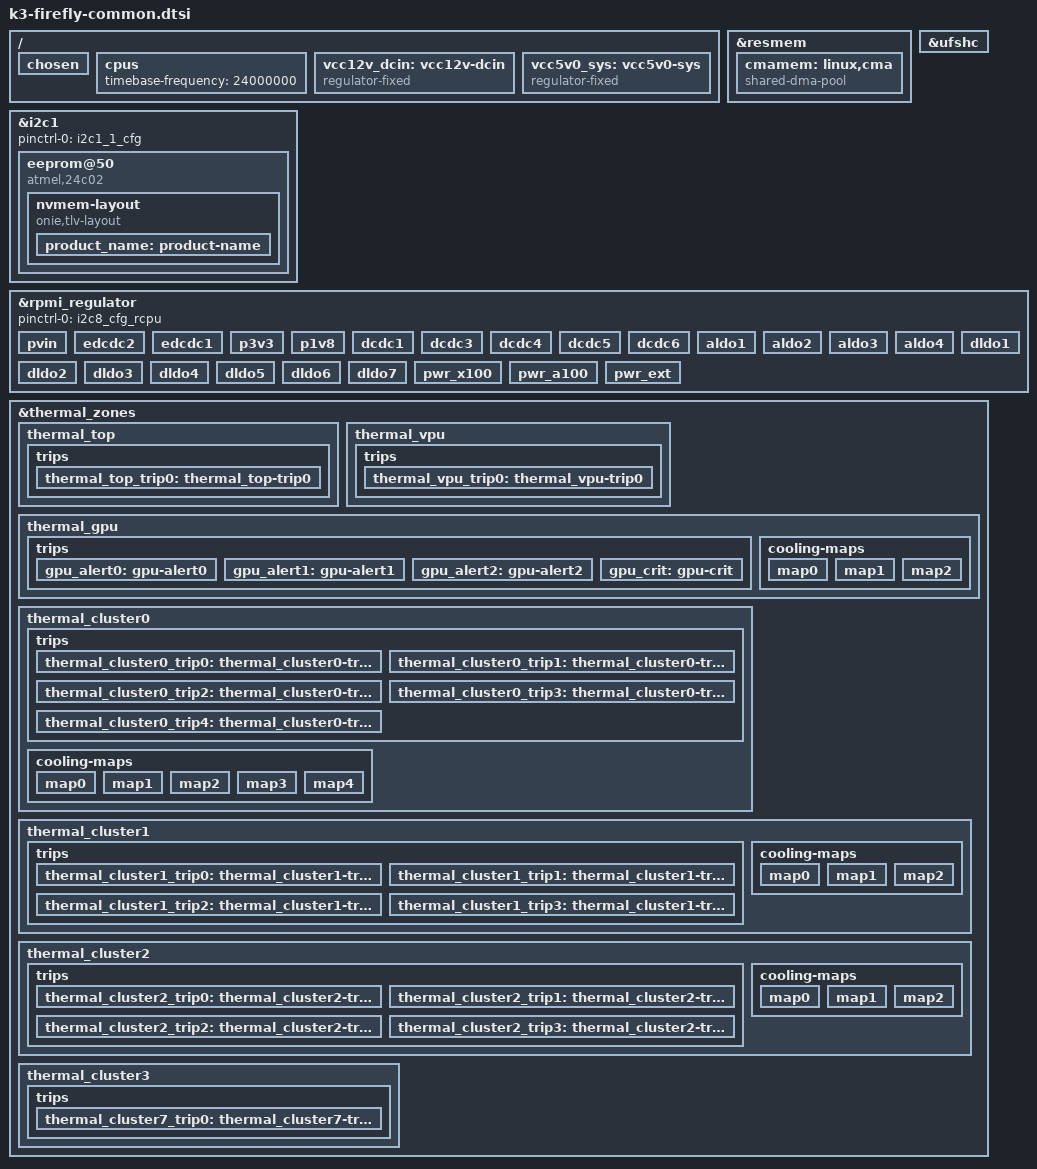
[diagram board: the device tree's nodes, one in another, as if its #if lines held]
// SPDX-License-Identifier: (GPL-2.0 OR MIT)
/* Copyright (c) 2025 Spacemit, Inc */

#include "k3.dtsi"
#include "k3-rdomain.dtsi"
#include "k3-pinctrl.dtsi"
#include "k3_opp_table.dtsi"
#include "dt-bindings/usb/pd.h"
#include <dt-bindings/input/input.h>

/ {
	chosen {
		bootargs = "earlycon=sbi console=ttyS0,115200 loglevel=8 random.trust_bootloader=1 unaligned_scalar_speed=fast unaligned_vector_speed=fast net.ifnames=0";
		rng-seed = <0x25d69b2 0xff555073 0xd23238ea 0x57aa5455 0x792478ed 0xa744f28e 0x6ba4fc54 0xa2bf20fc>;

		stdout-path = "serial0:115200";
	};

	cpus: cpus {
		#address-cells = <1>;
		#size-cells = <0>;
		timebase-frequency = <24000000>;
	};

	vcc12v_dcin: vcc12v-dcin {
		compatible = "regulator-fixed";
		regulator-name = "vcc12v_dcin";
		regulator-always-on;
		regulator-boot-on;
		regulator-min-microvolt = <12000000>;
		regulator-max-microvolt = <12000000>;
	};

	vcc5v0_sys: vcc5v0-sys {
		compatible = "regulator-fixed";
		regulator-name = "vcc5v0_sys";
		regulator-always-on;
		regulator-boot-on;
		regulator-min-microvolt = <5000000>;
		regulator-max-microvolt = <5000000>;
		vin-supply = <&vcc12v_dcin>;
	};
};

&resmem {
	/* global autoconfigured region for contiguous allocations */
	cmamem: linux,cma {
		compatible = "shared-dma-pool";
		reusable;
		size = <0 0x20000000>;
		alloc-ranges = <1 0x40000000 0 0x20000000>;
		linux,cma-default;
	};
};

&ufshc {
	status = "okay";
};

&i2c1 {
	pinctrl-names = "default";
	pinctrl-0 = <&i2c1_1_cfg>;
	status = "okay";

	eeprom@50 {
		compatible = "atmel,24c02";
		reg = <0x50>;
		read-only;
		status = "okay";

		nvmem-layout {
			compatible = "onie,tlv-layout";

			product_name: product-name {
			};
		};
	};
};

&rpmi_regulator {
	status = "okay";
	pinctrl-names = "default";
	pinctrl-0 = <&i2c8_cfg_rcpu>;

	pvin: pvin {
		regulator-min-microvolt = <5000000>;
		regulator-max-microvolt = <5000000>;
		regulator-always-on;
		regulator-boot-on;
	};

	edcdc2: edcdc2 {
		regulator-min-microvolt = <534000>;
		regulator-max-microvolt = <1005000>;
		regulator-always-on;
		regulator-boot-on;
	};

	edcdc1: edcdc1 {
		regulator-min-microvolt = <534000>;
		regulator-max-microvolt = <1005000>;
		regulator-always-on;
		regulator-boot-on;
	};

	p3v3: p3v3 {
		regulator-min-microvolt = <3300000>;
		regulator-max-microvolt = <3300000>;
		regulator-always-on;
		regulator-boot-on;
	};

	p1v8: p1v8 {
		regulator-min-microvolt = <1800000>;
		regulator-max-microvolt = <1800000>;
		regulator-always-on;
		regulator-boot-on;
	};

	dcdc1: dcdc1 {
		regulator-min-microvolt = <1050000>;
		regulator-max-microvolt = <1050000>;
		regulator-always-on;
		regulator-boot-on;
	};

	dcdc3: dcdc3 {
		regulator-min-microvolt = <800000>;
		regulator-max-microvolt = <800000>;
		regulator-always-on;
		regulator-boot-on;
	};

	dcdc4: dcdc4 {
		regulator-min-microvolt = <2100000>;
		regulator-max-microvolt = <2100000>;
		regulator-always-on;
		regulator-boot-on;
	};

	dcdc5: dcdc5 {
		regulator-min-microvolt = <1800000>;
		regulator-max-microvolt = <1800000>;
		regulator-always-on;
		regulator-boot-on;
	};

	dcdc6: dcdc6 {
		regulator-min-microvolt = <500000>;
		regulator-max-microvolt = <600000>;
		regulator-always-on;
		regulator-boot-on;
	};

	aldo1: aldo1 {
		regulator-min-microvolt = <1800000>;
		regulator-max-microvolt = <3300000>;
		regulator-always-on;
		regulator-boot-on;
	};

	aldo2: aldo2 {
		regulator-min-microvolt = <1800000>;
		regulator-max-microvolt = <1800000>;
		regulator-always-on;
		regulator-boot-on;
	};

	aldo3: aldo3 {
		regulator-min-microvolt = <500000>;
		regulator-max-microvolt = <3400000>;
	};

	aldo4: aldo4 {
		regulator-min-microvolt = <3300000>;
		regulator-max-microvolt = <3300000>;
		regulator-always-on;
		regulator-boot-on;
	};

	dldo1: dldo1 {
		regulator-min-microvolt = <1200000>;
		regulator-max-microvolt = <1200000>;
		regulator-always-on;
		regulator-boot-on;
	};

	dldo2: dldo2 {
		regulator-min-microvolt = <900000>;
		regulator-max-microvolt = <900000>;
		regulator-always-on;
		regulator-boot-on;
	};

	dldo3: dldo3 {
		regulator-min-microvolt = <800000>;
		regulator-max-microvolt = <800000>;
		regulator-always-on;
		regulator-boot-on;
	};

	dldo4: dldo4 {
		regulator-min-microvolt = <1800000>;
		regulator-max-microvolt = <1800000>;
		regulator-always-on;
		regulator-boot-on;
	};

	dldo5: dldo5 {
		regulator-min-microvolt = <1800000>;
		regulator-max-microvolt = <1800000>;
	};

	dldo6: dldo6 {
		regulator-min-microvolt = <1800000>;
		regulator-max-microvolt = <1800000>;
		regulator-always-on;
		regulator-boot-on;
	};

	dldo7: dldo7 {
		regulator-min-microvolt = <1800000>;
		regulator-max-microvolt = <1800000>;
		regulator-always-on;
		regulator-boot-on;
	};

	pwr_x100: pwr_x100 {
		regulator-min-microvolt = <3300000>;
		regulator-max-microvolt = <3300000>;
		regulator-always-on;
		regulator-boot-on;
	};

	pwr_a100: pwr_a100 {
		regulator-min-microvolt = <3300000>;
		regulator-max-microvolt = <3300000>;
		regulator-always-on;
		regulator-boot-on;
	};

	pwr_ext: pwr_ext {
		regulator-min-microvolt = <3300000>;
		regulator-max-microvolt = <3300000>;
		regulator-always-on;
		regulator-boot-on;
	};
};

&thermal_zones {
	thermal_top {
		polling-delay = <1000>;
		polling-delay-passive = <250>;
		thermal-sensors = <&thermal 0>;

		trips {
			thermal_top_trip0: thermal_top-trip0 {
				temperature = <40000>;
				hysteresis = <5000>;
				type = "passive";
			};
		};
	};

	thermal_vpu {
		polling-delay = <1000>;
		polling-delay-passive = <250>;
		thermal-sensors = <&thermal 2>;

		trips {
			thermal_vpu_trip0: thermal_vpu-trip0 {
				temperature = <40000>;
				hysteresis = <5000>;
				type = "passive";
			};
		};
	};

	thermal_gpu {
		polling-delay = <1000>;
		polling-delay-passive = <500>;
		thermal-sensors = <&thermal 3>;

		trips {
			gpu_alert0: gpu-alert0 {
				temperature = <65000>;
				hysteresis = <2000>;
				type = "passive";
			};

			gpu_alert1: gpu-alert1 {
				temperature = <75000>;
				hysteresis = <2000>;
				type = "passive";
			};

			gpu_alert2: gpu-alert2 {
				temperature = <85000>;
				hysteresis = <2000>;
				type = "passive";
			};

			gpu_crit: gpu-crit {
				temperature = <115000>;
				hysteresis = <2000>;
				type = "critical";
			};
		};

		cooling-maps {
			map0 {
				trip = <&gpu_alert0>;
				cooling-device = <&imggpu 0 1>;
			};

			map1 {
				trip = <&gpu_alert1>;
				cooling-device = <&imggpu 2 3>;
			};

			map2 {
				trip = <&gpu_alert2>;
				cooling-device = <&imggpu 4 5>;
			};
		};
	};

	thermal_cluster0 {
		polling-delay = <1000>;
		polling-delay-passive = <250>;
		thermal-sensors = <&thermal 4>;

		trips {
			thermal_cluster0_trip0: thermal_cluster0-trip0 {
				temperature = <35000>;
				hysteresis = <5000>;
				type = "active";
			};

			thermal_cluster0_trip1: thermal_cluster0-trip1 {
				temperature = <40000>;
				hysteresis = <5000>;
				type = "passive";
			};

			thermal_cluster0_trip2: thermal_cluster0-trip2 {
				temperature = <50000>;
				hysteresis = <5000>;
				type = "passive";
			};

			thermal_cluster0_trip3: thermal_cluster0-trip3 {
				temperature = <60000>;
				hysteresis = <5000>;
				type = "passive";
			};

			thermal_cluster0_trip4: thermal_cluster0-trip4 {
				temperature = <70000>;
				hysteresis = <5000>;
				type = "passive";
			};
		};

#ifdef FF_FAN
		cooling-maps {
			map0 {
				trip = <&thermal_cluster0_trip0>;
				cooling-device = <&ctf2301 0 50>;
			};

			map1 {
				trip = <&thermal_cluster0_trip1>;
				cooling-device = <&ctf2301 64 75>;
			};

			map2 {
				trip = <&thermal_cluster0_trip2>;
				cooling-device = <&ctf2301 102 128>;
			};

			map3 {
				trip = <&thermal_cluster0_trip3>;
				cooling-device = <&ctf2301 179 204>;
			};

			map4 {
				trip = <&thermal_cluster0_trip4>;
				cooling-device = <&ctf2301 255 255>;
			};
		};
#endif
	};

	thermal_cluster1 {
		polling-delay = <1000>;
		polling-delay-passive = <250>;
		thermal-sensors = <&thermal 5>;

		trips {
			thermal_cluster1_trip0: thermal_cluster1-trip0 {
				temperature = <85000>;
				hysteresis = <2000>;
				type = "active";
			};

			thermal_cluster1_trip1: thermal_cluster1-trip1 {
				temperature = <95000>;
				hysteresis = <2000>;
				type = "passive";
			};

			thermal_cluster1_trip2: thermal_cluster1-trip2 {
				temperature = <105000>;
				hysteresis = <2000>;
				type = "passive";
			};

			thermal_cluster1_trip3: thermal_cluster1-trip3 {
				temperature = <115000>;
				hysteresis = <2000>;
				type = "critical";
			};
		};

		cooling-maps {
			map0 {
				trip = <&thermal_cluster1_trip0>;
				cooling-device = <&cpu_0 2 2>,
						<&cpu_1 2 2>,
						<&cpu_2 2 2>,
						<&cpu_3 2 2>,
						<&cpu_4 2 2>,
						<&cpu_5 2 2>,
						<&cpu_6 2 2>,
						<&cpu_7 2 2>;
			};

			map1 {
				trip = <&thermal_cluster1_trip1>;
				cooling-device = <&cpu_0 3 5>,
						<&cpu_1 3 5>,
						<&cpu_2 3 5>,
						<&cpu_3 3 5>,
						<&cpu_4 3 5>,
						<&cpu_5 3 5>,
						<&cpu_6 3 5>,
						<&cpu_7 3 5>;
			};

			map2 {
				trip = <&thermal_cluster1_trip2>;
				cooling-device = <&cpu_0 6 8>,
						<&cpu_1 6 8>,
						<&cpu_2 6 8>,
						<&cpu_3 6 8>,
						<&cpu_4 6 8>,
						<&cpu_5 6 8>,
						<&cpu_6 6 8>,
						<&cpu_7 6 8>;
			};
		};
	};

	thermal_cluster2 {
		polling-delay = <1000>;
		polling-delay-passive = <250>;
		thermal-sensors = <&thermal 6>;

		trips {
			thermal_cluster2_trip0: thermal_cluster2-trip0 {
				temperature = <85000>;
				hysteresis = <2000>;
				type = "active";
			};

			thermal_cluster2_trip1: thermal_cluster2-trip1 {
				temperature = <95000>;
				hysteresis = <2000>;
				type = "passive";
			};

			thermal_cluster2_trip2: thermal_cluster2-trip2 {
				temperature = <105000>;
				hysteresis = <2000>;
				type = "passive";
			};

			thermal_cluster2_trip3: thermal_cluster2-trip3 {
				temperature = <115000>;
				hysteresis = <2000>;
				type = "critical";
			};
		};

		cooling-maps {
			map0 {
				trip = <&thermal_cluster2_trip0>;
				cooling-device = <&cpu_8 3 3>,
						<&cpu_9 3 3>,
						<&cpu_10 3 3>,
						<&cpu_11 3 3>,
						<&cpu_12 3 3>,
						<&cpu_13 3 3>,
						<&cpu_14 3 3>,
						<&cpu_15 3 3>;
			};

			map1 {
				trip = <&thermal_cluster2_trip1>;
				cooling-device = <&cpu_8 4 5>,
						<&cpu_9 4 5>,
						<&cpu_10 4 5>,
						<&cpu_11 4 5>,
						<&cpu_12 4 5>,
						<&cpu_13 4 5>,
						<&cpu_14 4 5>,
						<&cpu_15 4 5>;
			};

			map2 {
				trip = <&thermal_cluster2_trip2>;
				cooling-device = <&cpu_8 6 8>,
						<&cpu_9 6 8>,
						<&cpu_10 6 8>,
						<&cpu_11 6 8>,
						<&cpu_12 6 8>,
						<&cpu_13 6 8>,
						<&cpu_14 6 8>,
						<&cpu_15 6 8>;
			};
		};
	};

	thermal_cluster3 {
		polling-delay = <1000>;
		polling-delay-passive = <250>;
		thermal-sensors = <&thermal 7>;

		trips {
			thermal_cluster7_trip0: thermal_cluster7-trip0 {
				temperature = <40000>;
				hysteresis = <5000>;
				type = "passive";
			};
		};
	};
};
